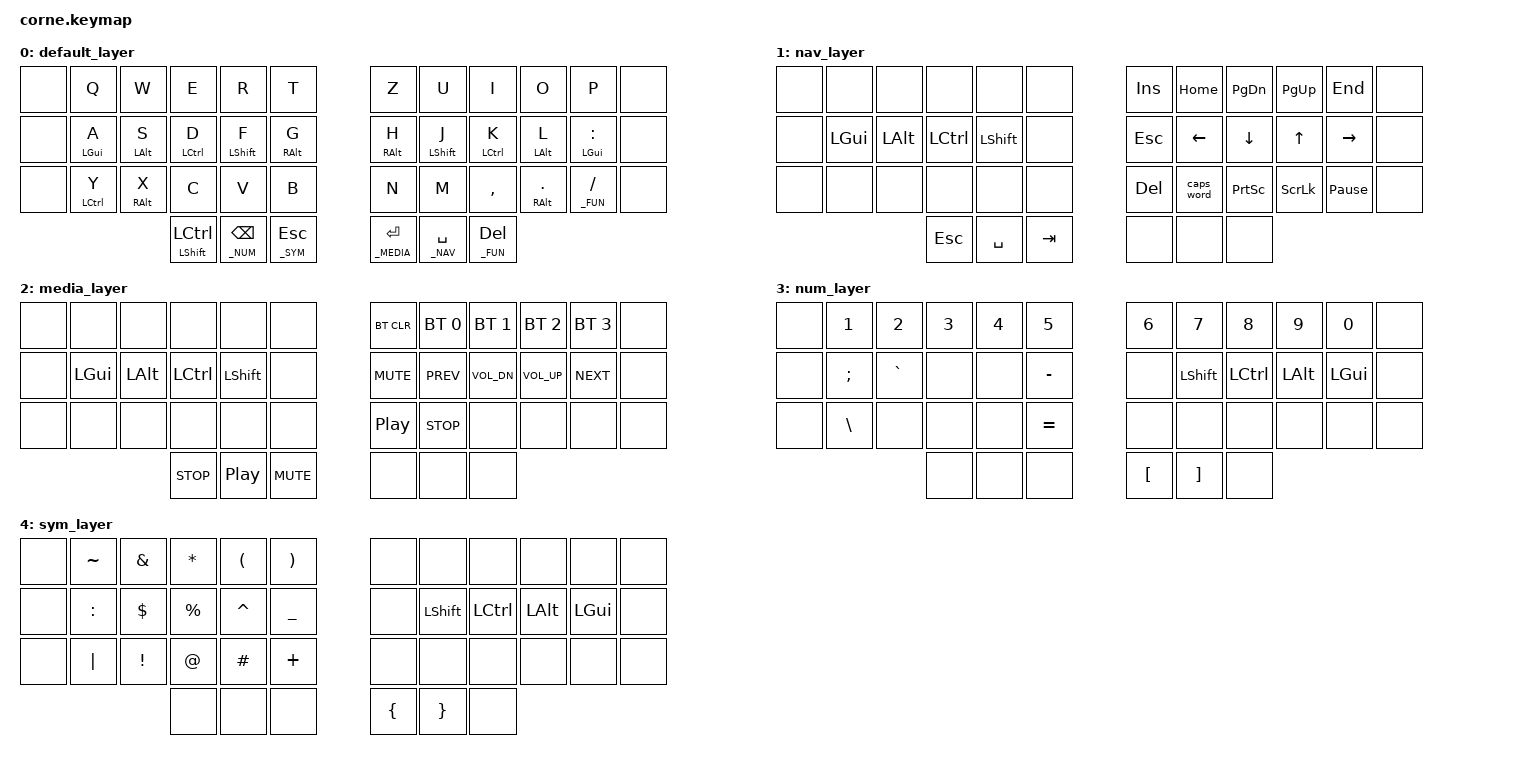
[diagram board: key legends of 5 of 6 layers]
/*
 * Copyright (c) 2020 The ZMK Contributors
 *
 * SPDX-License-Identifier: MIT
 */

#include <behaviors.dtsi>
#include <dt-bindings/zmk/keys.h>
#include <dt-bindings/zmk/bt.h>

#define _NAV 1
#define _MEDIA 2
#define _NUM 3
#define _SYM 4
#define _FUN 5

&mt {
    flavor = "tap-preferred";
    tapping_term_ms = <285>;
};

/ {
        keymap {
                compatible = "zmk,keymap";

                default_layer {
                        bindings = <
    &none           &kp Q           &kp W           &kp E           &kp R           &kp T           &kp Z           &kp U           &kp I           &kp O           &kp P           &none
    &none           &mt LGUI A      &mt LALT S      &mt LCTRL D     &mt LSHFT F     &mt RALT G      &mt RALT H      &mt LSHFT J     &mt LCTRL K     &mt LALT L      &mt LGUI COLON  &none
    &none           &mt LCTRL Y     &mt RALT X      &kp C           &kp V           &kp B           &kp N           &kp M           &kp COMMA       &mt RALT DOT    &lt _FUN FSLH   &none
                                                    &mt LSHFT LCTRL &lt _NUM BSPC   &lt _SYM ESC    &lt _MEDIA RET  &lt _NAV SPACE  &lt _FUN DEL
                        >;
                };

                nav_layer {
                        bindings = <
    &none           &none           &none           &none           &none           &none           &kp INS         &kp HOME        &kp PG_DN       &kp PG_UP       &kp END         &none
    &none           &kp LGUI        &kp LALT        &kp LCTRL       &kp LSHFT       &none           &kp ESC         &kp LEFT        &kp DOWN        &kp UP          &kp RIGHT       &none
    &none           &none           &none           &none           &none           &none           &kp DEL         &caps_word      &kp PSCRN       &kp SLCK        &kp PAUSE_BREAK &none
                                                    &kp ESC         &kp SPACE       &kp TAB         &none           &none           &none
                        >;
                };

                media_layer {
                        bindings = <
    &none           &none           &none           &none           &none           &none           &bt BT_CLR      &bt BT_SEL 0    &bt BT_SEL 1    &bt BT_SEL 2    &bt BT_SEL 3    &none
    &none           &kp LGUI        &kp LALT        &kp LCTRL       &kp LSHFT       &none           &kp C_MUTE      &kp C_PREV      &kp C_VOL_DN    &kp C_VOL_UP    &kp C_NEXT      &none
    &none           &none           &none           &none           &none           &none           &kp C_PP        &kp C_STOP      &none           &none           &none           &none
                                                    &kp C_STOP      &kp C_PP        &kp C_MUTE      &none           &none           &none
                        >;
                };

                num_layer {
                        bindings = <
    &none           &kp N1          &kp N2          &kp N3          &kp N4          &kp N5          &kp N6          &kp N7          &kp N8          &kp N9          &kp N0          &none
    &none           &kp SEMI        &kp GRAVE       &none           &none           &kp MINUS       &none           &kp LSHFT       &kp LCTRL       &kp LALT        &kp LGUI        &none
    &none           &kp BSLH        &none           &none           &none           &kp EQUAL       &none           &none           &none           &none           &none           &none
                                                    &none           &none           &none           &kp LBKT        &kp RBKT        &none
                        >;
                };

                sym_layer {
                        bindings = <
    &none           &kp TILDE       &kp AMPS        &kp ASTRK       &kp LPAR        &kp RPAR        &none           &none           &none           &none           &none           &none
    &none           &kp COLON       &kp DLLR        &kp PRCNT       &kp CARET       &kp UNDER       &none           &kp LSHFT       &kp LCTRL       &kp LALT        &kp LGUI        &none
    &none           &kp PIPE        &kp EXCL        &kp AT          &kp HASH        &kp PLUS        &none           &none           &none           &none           &none           &none
                                                    &none           &none           &none           &kp LBRC        &kp RBRC        &none
                        >;
                };

                fun_layer {
                        bindings = <
    &none           &bootloader     &none           &none           &none           &none           &none           &kp F1          &kp F2          &kp F3          &kp F4          &none
    &none           &kp LGUI        &kp LALT        &kp LCTRL       &kp LSHFT       &none           &none           &kp F5          &kp F6          &kp F7          &kp F8          &none
    &none           &none           &none           &none           &none           &none           &none           &kp F9          &kp F10         &kp F11         &kp F12         &none
                                                    &kp ESC         &kp SPACE       &kp TAB         &none           &kp RET         &kp BSPC        &kp DEL
                        >;
                };

        };
};
